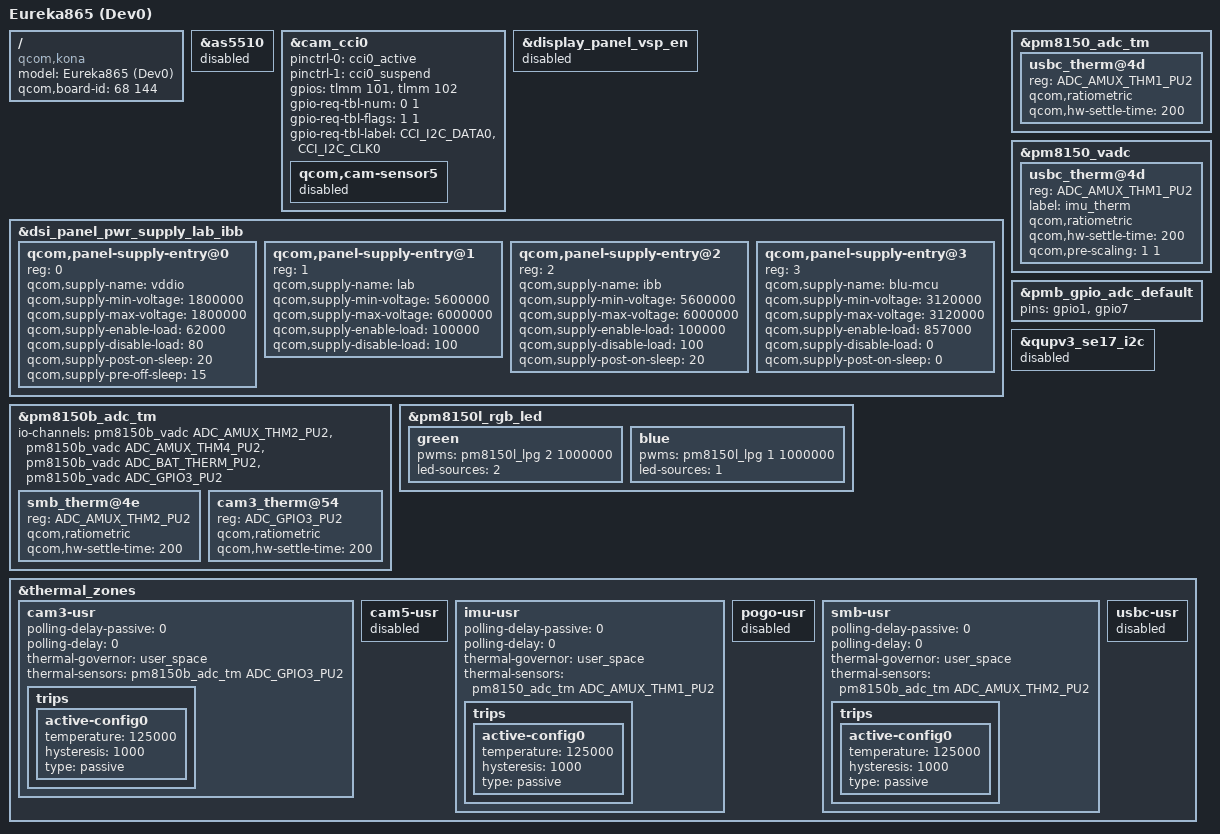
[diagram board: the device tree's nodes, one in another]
// SPDX-License-Identifier: GPL-2.0

/dts-v1/;
/plugin/;

#include "eureka865.dtsi"

/ {
	model = "Eureka865 (Dev0)";
	compatible = "qcom,kona";
	qcom,board-id = <68 144>;
};

&as5510 {
	status = "disabled";
};

&cam_cci0 {
	pinctrl-0 = <&cci0_active>;
	pinctrl-1 = <&cci0_suspend>;
	gpios = <&tlmm 101 0>,
		<&tlmm 102 0>;
	gpio-req-tbl-num = <0 1>;
	gpio-req-tbl-flags = <1 1>;
	gpio-req-tbl-label = "CCI_I2C_DATA0",
		"CCI_I2C_CLK0";

	qcom,cam-sensor5 {
		status = "disabled";
	};
};

&display_panel_vsp_en {
	status = "disabled";
};

&dsi_panel_pwr_supply_lab_ibb {
	qcom,panel-supply-entry@0 {
		reg = <0>;
		qcom,supply-name = "vddio";
		qcom,supply-min-voltage = <1800000>;
		qcom,supply-max-voltage = <1800000>;
		qcom,supply-enable-load = <62000>;
		qcom,supply-disable-load = <80>;
		qcom,supply-post-on-sleep = <20>;
		qcom,supply-pre-off-sleep = <15>;
	};

	qcom,panel-supply-entry@1 {
		reg = <1>;
		qcom,supply-name = "lab";
		qcom,supply-min-voltage = <5600000>;
		qcom,supply-max-voltage = <6000000>;
		qcom,supply-enable-load = <100000>;
		qcom,supply-disable-load = <100>;
	};

	qcom,panel-supply-entry@2 {
		reg = <2>;
		qcom,supply-name = "ibb";
		qcom,supply-min-voltage = <5600000>;
		qcom,supply-max-voltage = <6000000>;
		qcom,supply-enable-load = <100000>;
		qcom,supply-disable-load = <100>;
		qcom,supply-post-on-sleep = <20>;
	};

	qcom,panel-supply-entry@3 {
		reg = <3>;
		qcom,supply-name = "blu-mcu";
		qcom,supply-min-voltage = <3120000>;
		qcom,supply-max-voltage = <3120000>;
		qcom,supply-enable-load = <857000>;
		qcom,supply-disable-load = <0>;
		qcom,supply-post-on-sleep = <0>;
	};

};

&pm8150_adc_tm {
	/* actually imu_therm */
	usbc_therm@4d {
		reg = <ADC_AMUX_THM1_PU2>;
		qcom,ratiometric;
		qcom,hw-settle-time = <200>;
	};
};

&pm8150_vadc {
	/* actually imu_therm */
	usbc_therm@4d {
		reg = <ADC_AMUX_THM1_PU2>;
		label = "imu_therm";
		qcom,ratiometric;
		qcom,hw-settle-time = <200>;
		qcom,pre-scaling = <1 1>;
	};
};

&pm8150b_adc_tm {
	io-channels = <&pm8150b_vadc ADC_AMUX_THM2_PU2>,
		<&pm8150b_vadc ADC_AMUX_THM4_PU2>,
		<&pm8150b_vadc ADC_BAT_THERM_PU2>,
		<&pm8150b_vadc ADC_GPIO3_PU2>;

	smb_therm@4e {
		reg = <ADC_AMUX_THM2_PU2>;
		qcom,ratiometric;
		qcom,hw-settle-time = <200>;
	};

	cam3_therm@54 {
		/* Canyon right */
		reg = <ADC_GPIO3_PU2>;
		qcom,ratiometric;
		qcom,hw-settle-time = <200>;
	};
};

&pm8150l_rgb_led {
	green {
		pwms = <&pm8150l_lpg 2 1000000>;
		led-sources = <2>;
	};

	blue {
		pwms = <&pm8150l_lpg 1 1000000>;
		led-sources = <1>;
	};
};

&pmb_gpio_adc_default {
	pins = "gpio1", "gpio7";
};

&qupv3_se17_i2c {
	status = "disabled";
};

&thermal_zones {
	cam3-usr {
		/* Canyon right */
		polling-delay-passive = <0>;
		polling-delay = <0>;
		thermal-governor = "user_space";
		thermal-sensors = <&pm8150b_adc_tm ADC_GPIO3_PU2>;
		trips {
			active-config0 {
				temperature = <125000>;
				hysteresis = <1000>;
				type = "passive";
			};
		};
	};

	cam5-usr {
		status = "disabled";
	};

	imu-usr {
		polling-delay-passive = <0>;
		polling-delay = <0>;
		thermal-governor = "user_space";
		thermal-sensors = <&pm8150_adc_tm ADC_AMUX_THM1_PU2>;
		trips {
			active-config0 {
				temperature = <125000>;
				hysteresis = <1000>;
				type = "passive";
			};
		};
	};

	pogo-usr {
		status = "disabled";
	};

	smb-usr {
		polling-delay-passive = <0>;
		polling-delay = <0>;
		thermal-governor = "user_space";
		thermal-sensors = <&pm8150b_adc_tm ADC_AMUX_THM2_PU2>;
		trips {
			active-config0 {
				temperature = <125000>;
				hysteresis = <1000>;
				type = "passive";
			};
		};
	};

	usbc-usr {
		status = "disabled";
	};
};
